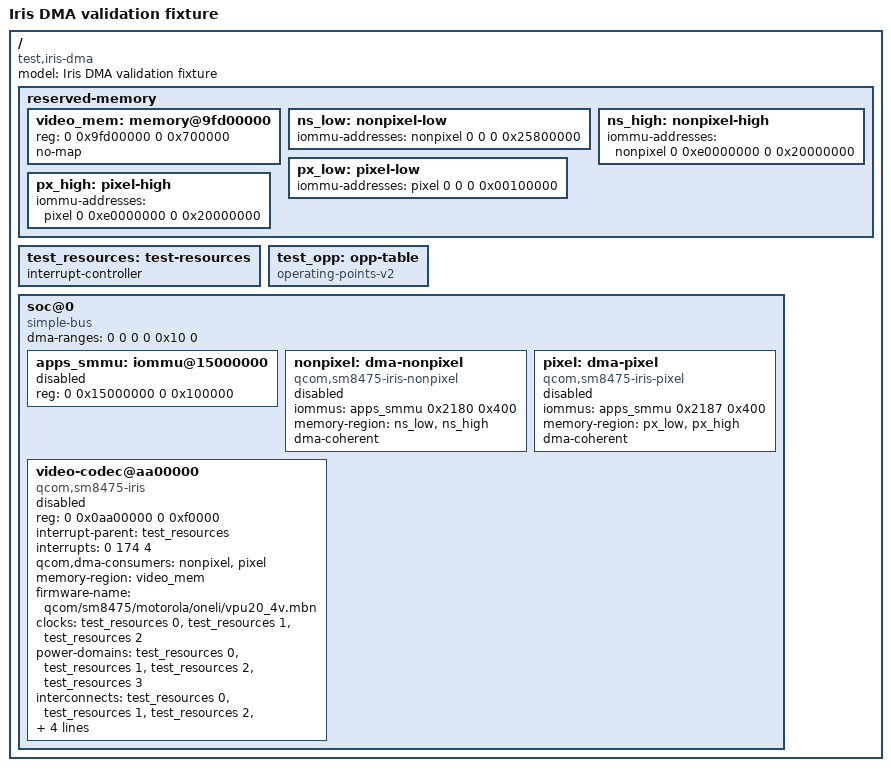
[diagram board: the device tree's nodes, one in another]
// SPDX-License-Identifier: GPL-2.0-only
/*
 * Disabled schema/OF fixture, NOT an installable board DT.
 * Bus hierarchy/cells/ranges: accepted integration
 * 2b5acf108ae37040ac1e652e029bb37f5609e886, oneli -> sm8475 -> sm8450.
 * Fake resource provider indices below are test data, not hardware mappings.
 * PAS physical address/size and nonsecure SID/mask come from stock evidence.
 */
/dts-v1/;
/ {
	model = "Iris DMA validation fixture";
	compatible = "test,iris-dma";
	#address-cells = <2>;
	#size-cells = <2>;

	reserved-memory {
		#address-cells = <2>;
		#size-cells = <2>;
		ranges;
		video_mem: memory@9fd00000 {
			reg = <0 0x9fd00000 0 0x700000>;
			no-map;
		};
		ns_low: nonpixel-low {
			iommu-addresses = <&nonpixel 0 0 0 0x25800000>;
		};
		ns_high: nonpixel-high {
			iommu-addresses = <&nonpixel 0 0xe0000000 0 0x20000000>;
		};
		px_low: pixel-low {
			iommu-addresses = <&pixel 0 0 0 0x00100000>;
		};
		px_high: pixel-high {
			iommu-addresses = <&pixel 0 0xe0000000 0 0x20000000>;
		};
	};

	/* Synthetic providers for schema isolation; no enabled hardware. */
	test_resources: test-resources {
		#clock-cells = <1>;
		#power-domain-cells = <1>;
		#reset-cells = <1>;
		#interconnect-cells = <1>;
		#interrupt-cells = <3>;
		interrupt-controller;
		#address-cells = <0>;
	};
	test_opp: opp-table {
		compatible = "operating-points-v2";
	};

	soc@0 {
		#address-cells = <2>;
		#size-cells = <2>;
		ranges = <0 0 0 0 0x10 0>;
		dma-ranges = <0 0 0 0 0x10 0>;
		compatible = "simple-bus";

		apps_smmu: iommu@15000000 {
			reg = <0 0x15000000 0 0x100000>;
			#iommu-cells = <2>;
			status = "disabled";
		};
		nonpixel: dma-nonpixel {
			compatible = "qcom,sm8475-iris-nonpixel";
			iommus = <&apps_smmu 0x2180 0x400>;
			memory-region = <&ns_low>, <&ns_high>;
			dma-coherent;
			status = "disabled";
		};
		pixel: dma-pixel {
			compatible = "qcom,sm8475-iris-pixel";
			iommus = <&apps_smmu 0x2187 0x400>;
			memory-region = <&px_low>, <&px_high>;
			dma-coherent;
			status = "disabled";
		};
		video-codec@aa00000 {
			compatible = "qcom,sm8475-iris";
			reg = <0 0x0aa00000 0 0xf0000>;
			interrupt-parent = <&test_resources>;
			interrupts = <0 174 4>;
			qcom,dma-consumers = <&nonpixel>, <&pixel>;
			memory-region = <&video_mem>;
			firmware-name = "qcom/sm8475/motorola/oneli/vpu20_4v.mbn";
			clocks = <&test_resources 0>, <&test_resources 1>, <&test_resources 2>;
			clock-names = "iface", "core", "vcodec0_core";
			power-domains = <&test_resources 0>, <&test_resources 1>,
					<&test_resources 2>, <&test_resources 3>;
			power-domain-names = "venus", "vcodec0", "mxc", "mmcx";
			interconnects = <&test_resources 0 &test_resources 1>,
					<&test_resources 2 &test_resources 3>;
			interconnect-names = "cpu-cfg", "video-mem";
			resets = <&test_resources 0>, <&test_resources 1>;
			reset-names = "bus", "core";
			operating-points-v2 = <&test_opp>;
			dma-coherent;
			status = "disabled";
		};
	};
};
